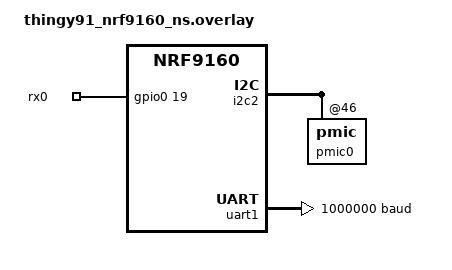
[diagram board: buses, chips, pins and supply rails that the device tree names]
/*
 * Copyright (c) 2022 Achim Kraus CloudCoap.net
 *
 * See the NOTICE file(s) distributed with this work for additional
 * information regarding copyright ownership.
 *
 * This program and the accompanying materials are made available under the
 * terms of the Eclipse Public License 2.0 which is available at
 * http: //www.eclipse.org/legal/epl-2.0
 *
 * SPDX-License-Identifier: EPL-2.0
 */

/ {

	chosen {
		nordic,modem-trace-uart = &uart1;
	};

	ins {
		compatible = "gpio-keys";
		rx0: uart0_rx {
			gpios = <&gpio0 19 0>;
		};
	};

	/*
	 * Map the devices to the aliases of the application.
	 */
	aliases {
		/* alias for sensor with SENSOR_CHAN_AMBIENT_TEMP channel */
		temperature-sensor = &bme680;
		/* alias for sensor with SENSOR_CHAN_HUMIDITY channel */
		humidity-sensor = &bme680;
		/* alias for sensor with SENSOR_CHAN_PRESS channel */
		pressure-sensor = &bme680;
		/* alias for sensor with SENSOR_CHAN_GAS_RES channel */
		gas-sensor = &bme680;

		/* alias for BME680 sensor to be used with Bosch BSEC library (IAQ Index Air Quality) */
		environment-sensor = &bme680;

		/* alias for sensor with SENSOR_CHAN_ACCEL_XYZ channels */
		accelerometer-sensor = &adxl362;

		/* alias for application eeprom */
//		appl-storage-eeprom = &eeprom0;

		/* alias for watchdog */
		watchdog0 = &wdt0;
		
		pmic = &pmic0; 
	};

};

&i2c2 {
	eeprom0: eeprom@50 {
		/* 24CW160 (16 kbit eeprom) */
		/* 0x8000 config register not accessible! If required, set size to 64K */
		compatible = "atmel,at24";
		reg = <0x50>;
		size = <DT_SIZE_K(2)>;
		pagesize = <32>;
		address-width = <16>;
		timeout = <5>;
		status = "disabled";
	};
    
	pmic0: pmic@46 {};
};

&uart1 {
	status = "okay";
	hw-flow-control;
	// important for trace uart!
	current-speed = < 1000000 >;
};

sensor_i2c: &i2c2 {};
